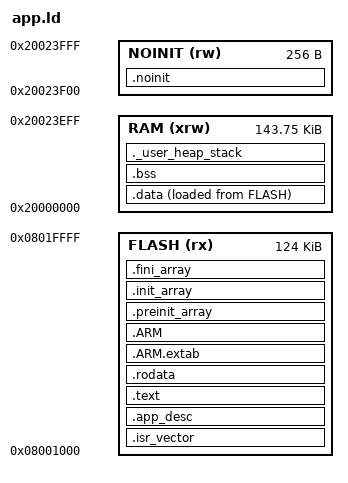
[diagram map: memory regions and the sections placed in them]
/* U3 application: bank 1 from 0x0800 1000 (after the 4 KB boot manager), see src/shared/u3_shared.h */
ENTRY(Reset_Handler)

MEMORY
{
  FLASH (rx)  : ORIGIN = 0x08001000, LENGTH = 124K
  RAM (xrw)   : ORIGIN = 0x20000000, LENGTH = 144K - 256
  NOINIT (rw) : ORIGIN = 0x20023F00, LENGTH = 256   /* persistent state + handover, see u3_shared.h */
}

_estack = ORIGIN(RAM) + LENGTH(RAM);
_Min_Heap_Size = 0x3000;   /* thelsing/knx: TX frames, the 2 KB flash erase-block buffer */
_Min_Stack_Size = 0x1000;

SECTIONS
{
  .isr_vector :
  {
    . = ALIGN(4);
    KEEP(*(.isr_vector))
    . = ALIGN(4);
  } >FLASH

  /* Fixed position: the boot manager reads the descriptor at base + 0x100 */
  .app_desc ORIGIN(FLASH) + 0x100 :
  {
    KEEP(*(.app_desc))
  } >FLASH

  .text :
  {
    . = ALIGN(4);
    *(.text)
    *(.text*)
    *(.glue_7)
    *(.glue_7t)
    *(.eh_frame)
    KEEP (*(.init))
    KEEP (*(.fini))
    . = ALIGN(4);
    _etext = .;
  } >FLASH

  .rodata :
  {
    . = ALIGN(4);
    *(.rodata)
    *(.rodata*)
    . = ALIGN(4);
  } >FLASH

  .ARM.extab : { *(.ARM.extab* .gnu.linkonce.armextab.*) } >FLASH
  .ARM : {
    __exidx_start = .;
    *(.ARM.exidx*)
    __exidx_end = .;
  } >FLASH

  .preinit_array :
  {
    PROVIDE_HIDDEN (__preinit_array_start = .);
    KEEP (*(.preinit_array*))
    PROVIDE_HIDDEN (__preinit_array_end = .);
  } >FLASH
  .init_array :
  {
    PROVIDE_HIDDEN (__init_array_start = .);
    KEEP (*(SORT(.init_array.*)))
    KEEP (*(.init_array*))
    PROVIDE_HIDDEN (__init_array_end = .);
  } >FLASH
  .fini_array :
  {
    PROVIDE_HIDDEN (__fini_array_start = .);
    KEEP (*(SORT(.fini_array.*)))
    KEEP (*(.fini_array*))
    PROVIDE_HIDDEN (__fini_array_end = .);
  } >FLASH

  _sidata = LOADADDR(.data);

  .data :
  {
    . = ALIGN(4);
    _sdata = .;
    *(.data)
    *(.data*)
    . = ALIGN(8);
    _edata = .;
  } >RAM AT> FLASH

  . = ALIGN(4);
  .bss :
  {
    _sbss = .;
    __bss_start__ = _sbss;
    *(.bss)
    *(.bss*)
    *(COMMON)
    . = ALIGN(4);
    _ebss = .;
    __bss_end__ = _ebss;
  } >RAM

  ._user_heap_stack :
  {
    . = ALIGN(8);
    PROVIDE ( end = . );
    PROVIDE ( _end = . );
    . = . + _Min_Heap_Size;
    . = . + _Min_Stack_Size;
    . = ALIGN(8);
  } >RAM

  .noinit (NOLOAD) :
  {
    KEEP(*(.noinit))
  } >NOINIT

  .ARM.attributes 0 : { *(.ARM.attributes) }
}
